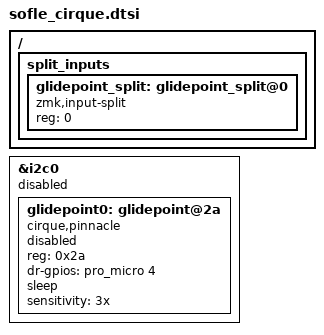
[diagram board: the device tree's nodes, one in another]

// Setup Cirque trackpad with i2c.
// Requires 3 pins; SCL, SDA and DR (data ready interrupt).
// Include this file in central and peripheral overlay file.
// Add CONFIG_I2C=y to each central and peripheral conf file.

&i2c0 {
    status = "disabled";
    glidepoint0: glidepoint@2a {
        compatible = "cirque,pinnacle";
        reg = <0x2a>;
        status = "disabled";
        dr-gpios = <&pro_micro 4 (GPIO_ACTIVE_HIGH)>;  // Pin 4 is unused with Sofle RGB PCB.

        sleep;
        //no-taps;
        //rotate-90;
        sensitivity = "3x";
        //no-smoothing; // badjeff cirque module fork tweak branch
    };
};

// ZMK Input Split
/ {
	split_inputs {
		#address-cells = <1>;
		#size-cells = <0>;
		glidepoint_split: glidepoint_split@0 {
			compatible = "zmk,input-split";
			reg = <0>;
		};
	};
};
